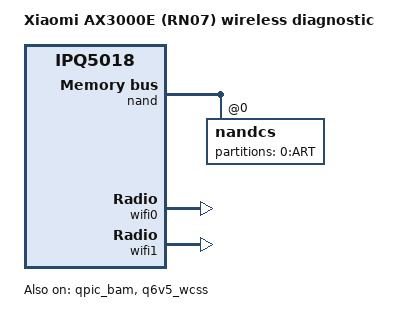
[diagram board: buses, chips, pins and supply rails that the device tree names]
// SPDX-License-Identifier: (GPL-2.0+)
/* RN07 phase2 diagnostic only. Not a persistent installation image.
 * Original board file and tested boot/load/memory reservations are unchanged.
 * The only exposed flash partition is read-only ART; no UBI/rootfs is exposed.
 * Radio firmware must match the pinned 2.7.0.1-01744 private image overlay.
 */
#include "ipq5018-rn07.dts"

/ {
    model = "Xiaomi AX3000E (RN07) wireless diagnostic";
};

&qpic_bam { status = "okay"; };
&nand {
    status = "okay";
    xiaomi,art-only-diagnostic;
    nandcs@0 {
        partitions {
            compatible = "fixed-partitions";
            #address-cells = <1>;
            #size-cells = <1>;
            /* Both saved MIBIB tables: offset 0x38 * 0x20000, 8 blocks. */
            partition@700000 {
                label = "0:ART";
                reg = <0x700000 0x100000>;
                read-only;
            };
        };
    };
};

&q6v5_wcss {
	memory-region = <&q6_mem_regions>;

	qcom,rproc = <&q6v5_wcss>;
	firmware = "IPQ5018/q6_fw.mdt";

	qcom,bootargs_smem = <507>;
	boot-args = </*       type: */ 0x2 /* PCIE1 */
		     /*     length: */ 4
		     /*      PD id: */ 2
		     /* reset GPIO: */ 18
		     /*   reserved: */ 0 0>;

	status = "ok";

	// IPQ5018
	q6_wcss_pd1: remoteproc_pd1@4ab000 {
		compatible = "qcom,ipq5018-wcss-ahb-mpd";

		resets =
			<&gcc GCC_WCSSAON_RESET>,
			<&gcc GCC_WCSS_BCR>,
			<&gcc GCC_CE_BCR>;
		reset-names =
			"wcss_aon_reset",
			"wcss_reset",
			"ce_reset";

		clocks =
			<&gcc GCC_WCSS_AHB_S_CLK>,
			<&gcc GCC_WCSS_ACMT_CLK>,
			<&gcc GCC_WCSS_AXI_M_CLK>;
		clock-names =
			"gcc_wcss_ahb_s_clk",
					"gcc_wcss_acmt_clk",
					"gcc_wcss_axi_m_clk";

		reg = <0x4ab000 0x20>;
		reg-names = "rmb";

		// qcom,halt-regs = <&tcsr_q6_block 0xa000 0xd000 0x0>;

		interrupts-extended =
			<&wcss_smp2p_in 8 0>,
			<&wcss_smp2p_in 9 0>,
			<&wcss_smp2p_in 12 0>,
			<&wcss_smp2p_in 11 0>;
		interrupt-names =
			"fatal",
			"ready",
			"spawn-ack",
			"stop-ack";

		qcom,smem-states =
			<&wcss_smp2p_out 8>,
			<&wcss_smp2p_out 9>,
			<&wcss_smp2p_out 10>;
		qcom,smem-state-names =
			"shutdown",
			"stop",
			"spawn";

		firmware = "IPQ5018/q6_fw.mdt";
		m3_firmware = "IPQ5018/m3_fw.mdt";
	};

	// QCN6122
	q6_wcss_pd2: remoteproc_pd2 {
		compatible = "qcom,ipq5018-wcss-pcie-mpd";

		interrupts-extended =
			<&wcss_smp2p_in 16 0>,
			<&wcss_smp2p_in 17 0>,
			<&wcss_smp2p_in 20 0>,
			<&wcss_smp2p_in 19 0>;
		interrupt-names =
			"fatal",
			"ready",
			"spawn-ack",
			"stop-ack";

		qcom,smem-states =
			<&wcss_smp2p_out 16>,
			<&wcss_smp2p_out 17>,
			<&wcss_smp2p_out 18>;
		qcom,smem-state-names =
			"shutdown",
			"stop",
			"spawn";

		firmware = "IPQ5018/q6_fw.mdt";
		m3_firmware = "qcn6122/m3_fw.mdt";
	};
};

&wifi0 {
	// IPQ5018
	qcom,multipd_arch;
	qcom,rproc = <&q6_wcss_pd1>;
	qcom,userpd-subsys-name = "q6v5_wcss_userpd1";

	qcom,board_id = <0x23>;

	// qcom,ath11k-fw-memory-mode = <0>;
	// qcom,bdf-addr = <0x4c400000>;
	// qcom,caldb-addr = <0x4d200000>;
	// qcom,m3-dump-addr = <0x4d400000>;

	qcom,ath11k-fw-memory-mode = <2>;
	qcom,bdf-addr = <0x4c400000>;

	status = "ok";
};

&wifi1 {
	// QCN6122
	qcom,multipd_arch;
	qcom,rproc = <&q6_wcss_pd2>;
	qcom,userpd-subsys-name = "q6v5_wcss_userpd2";

	qcom,board_id = <0x60>;

	// qcom,ath11k-fw-memory-mode = <0>;
	// qcom,bdf-addr = <0x4d500000>;
	// qcom,caldb-addr = <0x4e500000>;
	// qcom,m3-dump-addr = <0x4ea00000>;

	qcom,ath11k-fw-memory-mode = <2>;
	qcom,bdf-addr = <0x4d100000>;
	qcom,m3-dump-addr = <0x4df00000>;

	status = "ok";
};
